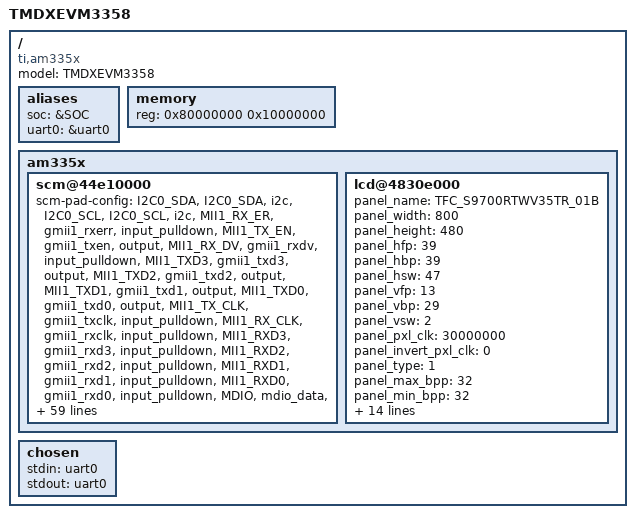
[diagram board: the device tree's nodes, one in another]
/*-
 * Copyright (c) 2012 Damjan Marion <dmarion@Freebsd.org>
 * All rights reserved.
 *
 * Redistribution and use in source and binary forms, with or without
 * modification, are permitted provided that the following conditions
 * are met:
 * 1. Redistributions of source code must retain the above copyright
 *    notice, this list of conditions and the following disclaimer.
 * 2. Redistributions in binary form must reproduce the above copyright
 *    notice, this list of conditions and the following disclaimer in the
 *    documentation and/or other materials provided with the distribution.
 *
 * THIS SOFTWARE IS PROVIDED BY THE AUTHOR AND CONTRIBUTORS ``AS IS'' AND
 * ANY EXPRESS OR IMPLIED WARRANTIES, INCLUDING, BUT NOT LIMITED TO, THE
 * IMPLIED WARRANTIES OF MERCHANTABILITY AND FITNESS FOR A PARTICULAR PURPOSE
 * ARE DISCLAIMED.  IN NO EVENT SHALL THE AUTHOR OR CONTRIBUTORS BE LIABLE
 * FOR ANY DIRECT, INDIRECT, INCIDENTAL, SPECIAL, EXEMPLARY, OR CONSEQUENTIAL
 * DAMAGES (INCLUDING, BUT NOT LIMITED TO, PROCUREMENT OF SUBSTITUTE GOODS
 * OR SERVICES; LOSS OF USE, DATA, OR PROFITS; OR BUSINESS INTERRUPTION)
 * HOWEVER CAUSED AND ON ANY THEORY OF LIABILITY, WHETHER IN CONTRACT, STRICT
 * LIABILITY, OR TORT (INCLUDING NEGLIGENCE OR OTHERWISE) ARISING IN ANY WAY
 * OUT OF THE USE OF THIS SOFTWARE, EVEN IF ADVISED OF THE POSSIBILITY OF
 * SUCH DAMAGE.
 * 
 * $FreeBSD$
 */

/dts-v1/;

/include/ "am335x.dtsi"

/ {
	model = "TMDXEVM3358";
	compatible = "ti,am335x";

	aliases {
		soc = &SOC;
		uart0 = &uart0;
	};

	memory {
		device_type = "memory";
		reg = < 0x80000000 0x10000000 >;	/* 256MB RAM */
	};

	am335x {
 		scm@44e10000 {
			/* Set of triplets < padname, muxname, padstate> */
			scm-pad-config =
				/* I2C0 */
				"I2C0_SDA", "I2C0_SDA","i2c",
				"I2C0_SCL", "I2C0_SCL","i2c",
				/* Ethernet */
				"MII1_RX_ER", "gmii1_rxerr", "input_pulldown",
				"MII1_TX_EN", "gmii1_txen", "output",
				"MII1_RX_DV", "gmii1_rxdv", "input_pulldown",
				"MII1_TXD3", "gmii1_txd3", "output",
				"MII1_TXD2", "gmii1_txd2", "output",
				"MII1_TXD1", "gmii1_txd1", "output",
				"MII1_TXD0", "gmii1_txd0", "output",
				"MII1_TX_CLK", "gmii1_txclk", "input_pulldown",
				"MII1_RX_CLK", "gmii1_rxclk", "input_pulldown",
				"MII1_RXD3", "gmii1_rxd3", "input_pulldown",
				"MII1_RXD2", "gmii1_rxd2", "input_pulldown",
				"MII1_RXD1", "gmii1_rxd1",  "input_pulldown",
				"MII1_RXD0", "gmii1_rxd0",  "input_pulldown",
				"MDIO", "mdio_data", "input_pullup",
				"MDC", "mdio_clk", "output_pullup",
				/* MMCSD0 */
				"MMC0_CMD", "mmc0_cmd", "input_pullup",
				"MMC0_CLK", "mmc0_clk", "input_pullup",
				"MMC0_DAT0", "mmc0_dat0", "input_pullup",
				"MMC0_DAT1", "mmc0_dat1", "input_pullup",
				"MMC0_DAT2", "mmc0_dat2", "input_pullup",
				"MMC0_DAT3", "mmc0_dat3", "input_pullup",
				/* GPIO */
				"GPMC_AD10", "gpio0_26", "input_pulldown",
				"GPMC_AD11", "gpio0_27", "input_pulldown",
				"GPMC_AD0", "gpio1_0", "input_pulldown",
				"GPMC_AD1", "gpio1_1", "input_pulldown",
				"GPMC_AD2", "gpio1_2", "input_pulldown",
				"GPMC_AD3", "gpio1_3", "input_pulldown",
				"GPMC_AD4", "gpio1_4", "input_pulldown",
				"GPMC_AD5", "gpio1_5", "input_pulldown",
				"GPMC_AD6", "gpio1_6", "input_pulldown",
				"GPMC_AD7", "gpio1_7", "input_pulldown",
				"GPMC_AD12", "gpio1_12", "input_pulldown",
				"GPMC_AD13", "gpio1_13", "input_pulldown",
				"GPMC_AD14", "gpio1_14", "input_pulldown",
				"GPMC_AD15", "gpio1_15", "input_pulldown",
				"GPMC_A0", "gpio1_16", "input_pulldown",
				"GPMC_A1", "gpio1_17", "input_pulldown",
				"GPMC_A5", "gpio1_21", "output", /* User LED 1 */
				"GPMC_A6", "gpio1_22", "output", /* User LED 2 */
				"GPMC_A7", "gpio1_23", "output", /* User LED 3 */
				"GPMC_A8", "gpio1_24", "output", /* User LED 4 */
				"GPMC_BEn1", "gpio1_28", "input_pulldown",
				"GPMC_CSn0", "gpio1_29", "input_pulldown",
				"GPMC_CSn1", "gpio1_30", "input_pulldown",
				"GPMC_CSn2", "gpio1_31", "input_pulldown",
				"MCASP0_FSR", "gpio3_19", "input_pulldown",
				"MCASP0_AHCLKX", "gpio3_21", "input_pulldown",
				/* TIMERs */
				"GPMC_ADVn_ALE", "timer4", "output",
				"GPMC_BEn0_CLE", "timer5", "output",
				"GPMC_WEn", "timer6", "output",
				"GPMC_OEn_REn", "timer7", "output",
				/* USB0 and USB1 */
				"USB0_DRVVBUS", "USB0_DRVVBUS", "output",
				"USB1_DRVVBUS", "USB1_DRVVBUS", "output",
				/* LCD */
				"GPMC_AD8", "lcd_data23", "output",
				"GPMC_AD9", "lcd_data22", "output",
				"GPMC_AD10", "lcd_data21", "output",
				"GPMC_AD11", "lcd_data20", "output",
				"GPMC_AD12", "lcd_data19", "output",
				"GPMC_AD13", "lcd_data18", "output",
				"GPMC_AD14", "lcd_data17", "output",
				"GPMC_AD15", "lcd_data16", "output",
				"GPMC_CLK", "lcd_memory_clk", "output",
				"LCD_DATA0", "lcd_data0", "output", 
				"LCD_DATA1", "lcd_data1", "output", 
				"LCD_DATA2", "lcd_data2", "output", 
				"LCD_DATA3", "lcd_data3", "output", 
				"LCD_DATA4", "lcd_data4", "output", 
				"LCD_DATA5", "lcd_data5", "output", 
				"LCD_DATA6", "lcd_data6", "output", 
				"LCD_DATA7", "lcd_data7", "output", 
				"LCD_DATA8", "lcd_data8", "output", 
				"LCD_DATA9", "lcd_data9", "output", 
				"LCD_DATA10", "lcd_data10", "output", 
				"LCD_DATA11", "lcd_data11", "output", 
				"LCD_DATA12", "lcd_data12", "output", 
				"LCD_DATA13", "lcd_data13", "output", 
				"LCD_DATA14", "lcd_data14", "output", 
				"LCD_DATA15", "lcd_data15", "output", 
				"LCD_VSYNC", "lcd_vsync", "output",
				"LCD_HSYNC", "lcd_hsync", "output",
				"LCD_PCLK", "lcd_pclk", "output",
				"LCD_AC_BIAS_EN", "lcd_ac_bias_en", "output",
				"ECAP0_IN_PWM0_OUT", "eCAP0_in_PWM0_out", "output";

 		};

		lcd@4830e000 {
			panel_name = "TFC_S9700RTWV35TR_01B";
			panel_width = <800>;
			panel_height = <480>;
			panel_hfp = <39>;
			panel_hbp = <39>;
			panel_hsw = <47>;
			panel_vfp = <13>;
			panel_vbp = <29>;
			panel_vsw = <2>;
			panel_pxl_clk = <30000000>;
			panel_invert_pxl_clk = <0>;
			panel_type = <1>; /* Active or passive, compatibility */
			panel_max_bpp = <32>; /* compatibility */
			panel_min_bpp =	<32>; /* compatibility */
			panel_shade = <1>; /* compatibility */
			ac_bias = <255>;
			ac_bias_intrpt = <0>;
			dma_burst_sz = <16>;
			bpp = <32>;
			fdd = <128>;
			tft_alt_mode = <0>; /* compatiblity */
			stn_565_mode = <0>; /* compatibility */
			mono_8bit_mode = <0>; /* compatibilty */
			invert_line_clock = <1>;
			invert_frm_clock = <1>;
			sync_edge = <0>;
			sync_ctrl = <1>;
			raster_order = <0>; /* compatibity */
		};

	};

	chosen {
		stdin = "uart0";
		stdout = "uart0";
	};
};
